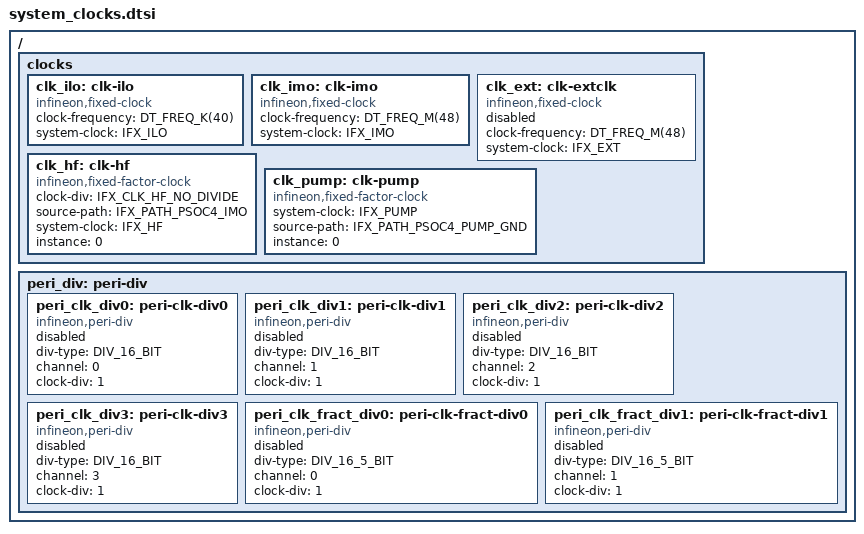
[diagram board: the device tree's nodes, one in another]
/*
 * SPDX-FileCopyrightText: <text>Copyright (c) 2026 Infineon Technologies AG,
 * or an affiliate of Infineon Technologies AG. All rights reserved.</text>
 *
 * SPDX-License-Identifier: Apache-2.0
 */

#define DIV_16_BIT   1
#define DIV_16_5_BIT 2
#define DIV_24_5_BIT 3

#include <zephyr/dt-bindings/clock/ifx_clock_source_common.h>
#include <zephyr/dt-bindings/clock/ifx_clock_source_psoc4xx.h>
#include <freq.h>

/ {
	clocks {
		/* Internal low-speed oscillator (ILO) */
		clk_ilo: clk-ilo {
			#clock-cells = <0>;
			compatible = "infineon,fixed-clock";
			clock-frequency = <DT_FREQ_K(40)>;
			system-clock = <IFX_ILO>;
			status = "okay";
		};

		/* Internal main oscillator (IMO) */
		clk_imo: clk-imo {
			#clock-cells = <0>;
			compatible = "infineon,fixed-clock";
			clock-frequency = <DT_FREQ_M(48)>;
			system-clock = <IFX_IMO>;
			status = "okay";
		};

		/* External clock (EXTCLK) */
		clk_ext: clk-extclk {
			#clock-cells = <0>;
			compatible = "infineon,fixed-clock";
			clock-frequency = <DT_FREQ_M(48)>;
			system-clock = <IFX_EXT>;
			status = "disabled";
		};

		clk_hf: clk-hf {
			#clock-cells = <0>;
			compatible = "infineon,fixed-factor-clock";
			clock-div = <IFX_CLK_HF_NO_DIVIDE>;
			source-path = <IFX_PATH_PSOC4_IMO>;
			system-clock = <IFX_HF>;
			instance = <0>;
			status = "okay";
		};

		clk_pump: clk-pump {
			#clock-cells = <0>;
			compatible = "infineon,fixed-factor-clock";
			system-clock = <IFX_PUMP>;
			source-path = <IFX_PATH_PSOC4_PUMP_GND>;
			instance = <0>;
			status = "okay";
		};
	};

	peri_div: peri-div {
		/* 4 x 16-bit dividers (PERI_PCLK_DIV_16_NR) */
		peri_clk_div0: peri-clk-div0 {
			#clock-cells = <0>;
			compatible = "infineon,peri-div";
			div-type = <DIV_16_BIT>;
			channel = <0>;
			clock-div = <1>;
			status = "disabled";
		};

		peri_clk_div1: peri-clk-div1 {
			#clock-cells = <0>;
			compatible = "infineon,peri-div";
			div-type = <DIV_16_BIT>;
			channel = <1>;
			clock-div = <1>;
			status = "disabled";
		};

		peri_clk_div2: peri-clk-div2 {
			#clock-cells = <0>;
			compatible = "infineon,peri-div";
			div-type = <DIV_16_BIT>;
			channel = <2>;
			clock-div = <1>;
			status = "disabled";
		};

		peri_clk_div3: peri-clk-div3 {
			#clock-cells = <0>;
			compatible = "infineon,peri-div";
			div-type = <DIV_16_BIT>;
			channel = <3>;
			clock-div = <1>;
			status = "disabled";
		};

		/* 2 x 16.5-bit fractional dividers (PERI_PCLK_DIV_16_5_NR) */
		peri_clk_fract_div0: peri-clk-fract-div0 {
			#clock-cells = <0>;
			compatible = "infineon,peri-div";
			div-type = <DIV_16_5_BIT>;
			channel = <0>;
			clock-div = <1>;
			status = "disabled";
		};

		peri_clk_fract_div1: peri-clk-fract-div1 {
			#clock-cells = <0>;
			compatible = "infineon,peri-div";
			div-type = <DIV_16_5_BIT>;
			channel = <1>;
			clock-div = <1>;
			status = "disabled";
		};
	};
};
